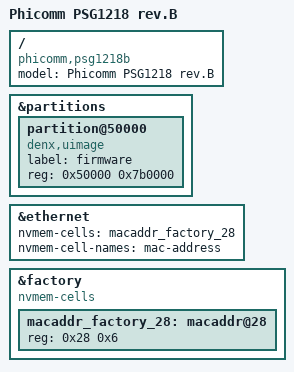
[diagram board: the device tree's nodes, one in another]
#include "mt7620a_phicomm_k2x.dtsi"

/ {
	compatible = "phicomm,psg1218b", "phicomm,psg1218", "ralink,mt7620a-soc";
	model = "Phicomm PSG1218 rev.B";
};

&partitions {
	partition@50000 {
		compatible = "denx,uimage";
		label = "firmware";
		reg = <0x50000 0x7b0000>;
	};
};

&ethernet {
	nvmem-cells = <&macaddr_factory_28>;
	nvmem-cell-names = "mac-address";
};

&factory {
	compatible = "nvmem-cells";
	#address-cells = <1>;
	#size-cells = <1>;

	macaddr_factory_28: macaddr@28 {
		reg = <0x28 0x6>;
	};
};
